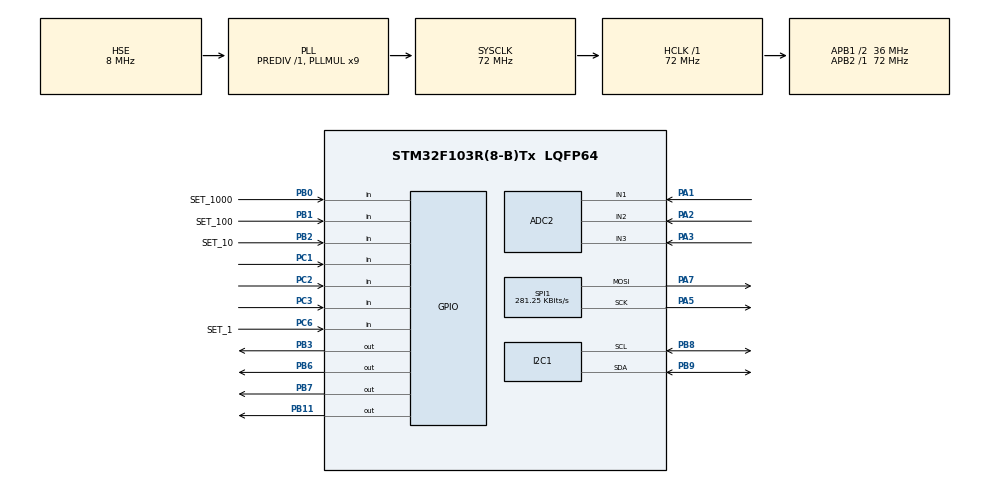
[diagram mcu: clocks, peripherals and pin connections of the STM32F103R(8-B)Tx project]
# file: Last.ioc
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ADC2.Channel-0\#ChannelRegularConversion=ADC_CHANNEL_1
ADC2.Channel-1\#ChannelRegularConversion=ADC_CHANNEL_2
ADC2.Channel-2\#ChannelRegularConversion=ADC_CHANNEL_3
ADC2.NbrOfConversion=3
ADC2.NbrOfConversionFlag=1
ADC2.Rank-0\#ChannelRegularConversion=1
ADC2.Rank-1\#ChannelRegularConversion=2
ADC2.Rank-2\#ChannelRegularConversion=3
ADC2.SamplingTime-0\#ChannelRegularConversion=ADC_SAMPLETIME_28CYCLES_5
ADC2.SamplingTime-1\#ChannelRegularConversion=ADC_SAMPLETIME_28CYCLES_5
ADC2.SamplingTime-2\#ChannelRegularConversion=ADC_SAMPLETIME_28CYCLES_5
Mcu.Family=STM32F1
Mcu.Name=STM32F103R(8-B)Tx
Mcu.Package=LQFP64
NVIC.PriorityGroup=NVIC_PRIORITYGROUP_4
NVIC.TIM3_IRQn=true\:0\:0\:false\:false\:true\:true\:true\:true
PA1.Signal=ADCx_IN1
PA13.Mode=Serial_Wire
PA13.Signal=SYS_JTMS-SWDIO
PA14.Mode=Serial_Wire
PA14.Signal=SYS_JTCK-SWCLK
PA2.Signal=ADCx_IN2
PA3.Signal=ADCx_IN3
PA5.Mode=TX_Only_Simplex_Unidirect_Master
PA5.Signal=SPI1_SCK
PA7.Mode=TX_Only_Simplex_Unidirect_Master
PA7.Signal=SPI1_MOSI
PB0.GPIO_Label=SET_1000
PB0.GPIO_PuPd=GPIO_PULLDOWN
PB0.Signal=GPIO_Input
PB1.GPIO_Label=SET_100
PB1.GPIO_PuPd=GPIO_PULLDOWN
PB1.Signal=GPIO_Input
PB11.GPIO_PuPd=GPIO_PULLDOWN
PB11.Signal=GPIO_Output
PB2.GPIO_Label=SET_10
PB2.GPIO_PuPd=GPIO_PULLDOWN
PB2.Signal=GPIO_Input
PB3.GPIO_Speed=GPIO_SPEED_FREQ_HIGH
PB3.Signal=GPIO_Output
PB6.Signal=GPIO_Output
PB7.Signal=GPIO_Output
PB8.Mode=I2C
PB8.Signal=I2C1_SCL
PB9.Mode=I2C
PB9.Signal=I2C1_SDA
PC1.GPIO_PuPd=GPIO_PULLDOWN
PC1.Signal=GPIO_Input
PC2.GPIO_PuPd=GPIO_PULLDOWN
PC2.Signal=GPIO_Input
PC3.GPIO_PuPd=GPIO_PULLDOWN
PC3.Signal=GPIO_Input
PC6.GPIO_Label=SET_1
PC6.GPIO_PuPd=GPIO_PULLDOWN
PC6.Signal=GPIO_Input
PD0-OSC_IN.Mode=HSE-External-Oscillator
PD0-OSC_IN.Signal=RCC_OSC_IN
PD1-OSC_OUT.Mode=HSE-External-Oscillator
PD1-OSC_OUT.Signal=RCC_OSC_OUT
ProjectManager.HeapSize=0x200
ProjectManager.StackSize=0x400
ProjectManager.TargetToolchain=STM32CubeIDE
RCC.ADCPresc=RCC_ADCPCLK2_DIV6
RCC.AHBFreq_Value=72000000
RCC.APB1CLKDivider=RCC_HCLK_DIV2
RCC.APB1Freq_Value=36000000
RCC.APB1TimFreq_Value=72000000
RCC.APB2Freq_Value=72000000
RCC.APB2TimFreq_Value=72000000
RCC.HCLKFreq_Value=72000000
RCC.PLLMUL=RCC_PLL_MUL9
RCC.PLLSourceVirtual=RCC_PLLSOURCE_HSE
RCC.SYSCLKFreq_VALUE=72000000
RCC.SYSCLKSource=RCC_SYSCLKSOURCE_PLLCLK
RCC.USBFreq_Value=72000000
SH.ADCx_IN1.0=ADC2_IN1,IN1
SH.ADCx_IN2.0=ADC2_IN2,IN2
SH.ADCx_IN3.0=ADC2_IN3,IN3
SPI1.BaudRatePrescaler=SPI_BAUDRATEPRESCALER_256
SPI1.CalculateBaudRate=281.25 KBits/s
SPI1.Direction=SPI_DIRECTION_2LINES
SPI1.Mode=SPI_MODE_MASTER
SPI1.VirtualType=VM_MASTER
TIM1.AutoReloadPreload=TIM_AUTORELOAD_PRELOAD_ENABLE
TIM1.Period=0xffff-1
TIM1.Prescaler=72-1
TIM2.AutoReloadPreload=TIM_AUTORELOAD_PRELOAD_ENABLE
TIM2.Period=65535-1
TIM2.Prescaler=72-1
TIM3.AutoReloadPreload=TIM_AUTORELOAD_PRELOAD_ENABLE
TIM3.Period=10
TIM3.Prescaler=7199
TIM4.AutoReloadPreload=TIM_AUTORELOAD_PRELOAD_ENABLE
TIM4.Period=255
TIM4.Prescaler=47999
VP_TIM1_VS_ClockSourceINT.Mode=Internal
VP_TIM2_VS_ClockSourceINT.Mode=Internal
VP_TIM3_VS_ClockSourceINT.Mode=Internal
VP_TIM4_VS_ClockSourceINT.Mode=Internal
board=custom

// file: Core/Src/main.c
/* USER CODE BEGIN Header */
/**
 ******************************************************************************
 * @file           : main.c
 * @brief          : Main program body
 ******************************************************************************
 * @attention
 *
 * Copyright (c) 2024 STMicroelectronics.
 * All rights reserved.
 *
 * This software is licensed under terms that can be found in the LICENSE file
 * in the root directory of this software component.
 * If no LICENSE file comes with this software, it is provided AS-IS.
 *
 ******************************************************************************
 */
/* USER CODE END Header */
#include "main.h"

/* USER CODE BEGIN Includes */
#include "ssd1306_fonts.h"
#include "ssd1306_tests.h"
#include "stdio.h"
#include "math.h"
/* USER CODE END Includes */

/* USER CODE BEGIN PD */
#define DS18B20_PORT GPIOB
#define DS18B20_PIN GPIO_PIN_14
#define ADC_BUF_SIZE 4
#define VREF 3310
#define DELAY_COND 6
#define DELAY_MOIST 1
#define BASELINE_TEMP 25.0
#define TEMP_COMP_COEFF 0.02  // 2% per degree Celsius
#define PI 3.14

/* USER CODE END PD */

ADC_HandleTypeDef hadc2;

I2C_HandleTypeDef hi2c1;

SPI_HandleTypeDef hspi1;

TIM_HandleTypeDef htim1;
TIM_HandleTypeDef htim2;
TIM_HandleTypeDef htim3;
TIM_HandleTypeDef htim4;

/* USER CODE BEGIN PV */
float EC_FACTOR;
uint32_t delay_time = 20000; // Initial delay time in microseconds
uint32_t delay_band = 1000; // Initial delay band in microseconds
uint8_t i=0;
uint8_t j=0;
uint8_t data_rdy=0;
uint32_t counter=0;
uint32_t counter2=0;
uint16_t counterFREQ=0;
int32_t PWM_loop=0;
uint16_t timeout=0;
float moist_offset=0;
float av_moist_sum=0;
float final_average_cond=0;
float av_cond=0;
float conductivity=0;
float resistance=0;
float av_moist=0;
float percentage_moist=0;
float percentage_moist2=0;
float Temp=0;
float Temp2=0;
float Temperature=0;
uint8_t Presence=0;
uint8_t Temp_byte1,Temp_byte2;
uint16_t TEMP =0;;
uint16_t TempInt;

const float CALIBRATION_FACTORX1=0.86;
const float CALIBRATION_FACTORX10=0.50;
const float CALIBRATION_FACTORX100=0.09;
const float CALIBRATION_FACTORX1000=0.01;

char bufferResistance[200];
char bufferConduct[200];
char bufferConduct2[200];
char bufferMoist[200];
char bufferTemp[200];
char bufferDs18b20[200];
char bufferTempInside[200];
char bufferVref[200];
char bufferDS18B20[200];
char bufferSET1[200];
char bufferSET10[200];
char bufferSET100[200];
char bufferSET1000[200];
char bufferFREQ[200];
char adcbuffer1[20];
char adcbuffer2[20];
uint8_t SET1=0;
uint8_t SET10=0;
uint8_t SET100=0;
uint8_t SET1000=0;
uint16_t conductraw=0;
uint16_t tempraw=0;
uint16_t moistureraw=0;
uint32_t value[3]; // adc valuyes
float temp1;//
float MIN_VOLTAGE = 600;
float MAX_VOLTAGE = 2130;
uint32_t adc_buffer[ADC_BUF_SIZE];
float voltage_buffer[ADC_BUF_SIZE];
uint8_t adc_ready=0;
uint8_t pwmflagfinished=0;
volatile uint8_t counterflagPWM=0;
volatile uint8_t counterflagPWM2=0;

uint32_t cond;
uint32_t vref_int_mv;
uint32_t moist;
uint32_t inTempC;
/* USER CODE END PV */

void SystemClock_Config(void);
static void MX_GPIO_Init(void);
static void MX_I2C1_Init(void);
static void MX_ADC2_Init(void);
static void MX_TIM1_Init(void);
static void MX_TIM4_Init(void);
static void MX_TIM3_Init(void);
static void MX_TIM2_Init(void);
static void MX_SPI1_Init(void);
/* USER CODE BEGIN PFP */
float new_calculateECSET1(float voltage,float Temp){
	const float voltagePerOhm = 20;  // Voltage increase per ohm
	float resistance = voltage / voltagePerOhm;
	float resistivity = resistance * (6.0*3.14);
	float uncompensatedConductivity  = 0;
	if (resistivity != 0) {
		uncompensatedConductivity  = (1 / resistivity) * 1000;  // Convert S/m to mS/cm
	}
	float tempCompensationFactor = 1 + (TEMP_COMP_COEFF * (Temp - BASELINE_TEMP));
	float compensatedConductivity = uncompensatedConductivity * tempCompensationFactor;
	return compensatedConductivity;
}
float new_calculateRSET1(float voltage){
	const float voltagePerOhm = 20;  // Voltage increase per ohm
	float resistance = voltage / voltagePerOhm;
	return resistance;
}
float new_calculateECSET10(float voltage,float Temp){
	const float voltagePerOhm = 3.1;  // Voltage increase per ohm
	float resistance = voltage / voltagePerOhm;
	float resistivity = resistance * (6.0*3.14);
	float uncompensatedConductivity  = 0;
	if (resistivity != 0) {
		uncompensatedConductivity  = (1 / resistivity) * 1000;  // Convert S/m to mS/cm
	}
	float tempCompensationFactor = 1 + (TEMP_COMP_COEFF * (Temp - BASELINE_TEMP));
	float compensatedConductivity = uncompensatedConductivity * tempCompensationFactor;
	return compensatedConductivity;
}
float new_calculateRSET10(float voltage){
	const float voltagePerOhm = 3.1;  // Voltage increase per ohm
	float resistance = voltage / voltagePerOhm;
	return resistance;
}
float new_calculateECSET100(float voltage,float Temp){
	const float voltagePerOhm = 0.31;  // Voltage increase per ohm
	float resistance = voltage / voltagePerOhm;
	float resistivity = resistance * (6.0*3.14);
	float uncompensatedConductivity  = 0;
	if (resistivity != 0) {
		uncompensatedConductivity  = (1 / resistivity) * 1000000;  // Convert S/m to uS/cm
	}
	float tempCompensationFactor = 1 + (TEMP_COMP_COEFF * (Temp - BASELINE_TEMP));
	float compensatedConductivity = uncompensatedConductivity * tempCompensationFactor;
	return compensatedConductivity;
}
float new_calculateRSET100(float voltage){
	const float voltagePerOhm = 0.31;  // Voltage increase per ohm
	float resistance = voltage / voltagePerOhm;
	return resistance;
}
float new_calculateECSET1000(float voltage,float Temp){
	const float voltagePerOhm = 0.031;  // Voltage increase per ohm
	float resistance = voltage / voltagePerOhm;
	float resistivity = resistance * (6.0*3.14);
	float uncompensatedConductivity  = 0;
	if (resistivity != 0) {
		uncompensatedConductivity  = (1 / resistivity) * 1000000;  // Convert S/m to uS/cm
	}
	float tempCompensationFactor = 1 + (TEMP_COMP_COEFF * (Temp - BASELINE_TEMP));
	float compensatedConductivity = uncompensatedConductivity * tempCompensationFactor;
	return compensatedConductivity;
}
float new_calculateRSET1000(float voltage){
	const float voltagePerOhm = 0.031;  // Voltage increase per ohm
	float resistance = voltage / voltagePerOhm;
	return resistance;
}

float calculateECSET1(float voltage,float Temp) {
	if((voltage>2900)&&(voltage<=3000))
	{
		const float voltagePerOhm = 0.1;  // Voltage increase per ohm
		float resistance = voltage / voltagePerOhm;
		float uncompensatedConductivity  = 0;
		if (resistance != 0) {
			uncompensatedConductivity  = (1 / resistance) * 10;  // Convert S/m to mS/cm
		}
		float tempCompensationFactor = 1 + (TEMP_COMP_COEFF * (Temp - BASELINE_TEMP));
		float compensatedConductivity = uncompensatedConductivity * tempCompensationFactor;
		return compensatedConductivity;
	}
	if((voltage>2600)&&(voltage<=2900))
	{
		const float voltagePerOhm = 0.5;  // Voltage increase per ohm
		float resistance = voltage / voltagePerOhm;
		float uncompensatedConductivity  = 0;
		if (resistance != 0) {
			uncompensatedConductivity  = (1 / resistance) * 10;  // Convert S/m to mS/cm
		}
		float tempCompensationFactor = 1 + (TEMP_COMP_COEFF * (Temp - BASELINE_TEMP));
		float compensatedConductivity = uncompensatedConductivity * tempCompensationFactor;
		return compensatedConductivity;
	}
	if((voltage>2300)&&(voltage<=2600))
	{
		const float voltagePerOhm = 5;  // Voltage increase per ohm
		float resistance = voltage / voltagePerOhm;
		float uncompensatedConductivity  = 0;
		if (resistance != 0) {
			uncompensatedConductivity  = (1 / resistance) * 10;  // Convert S/m to mS/cm
		}
		float tempCompensationFactor = 1 + (TEMP_COMP_COEFF * (Temp - BASELINE_TEMP));
		float compensatedConductivity = uncompensatedConductivity * tempCompensationFactor;
		return compensatedConductivity;
	}
	if((voltage>2000)&&(voltage<=2300))
	{
		const float voltagePerOhm = 20;  // Voltage increase per ohm
		float resistance = voltage / voltagePerOhm;
		float uncompensatedConductivity  = 0;
		if (resistance != 0) {
			uncompensatedConductivity  = (1 / resistance) * 10;  // Convert S/m to mS/cm
		}
		float tempCompensationFactor = 1 + (TEMP_COMP_COEFF * (Temp - BASELINE_TEMP));
		float compensatedConductivity = uncompensatedConductivity * tempCompensationFactor;
		return compensatedConductivity;
	}
	if((voltage>1700)&&(voltage<=2000))
	{
		const float voltagePerOhm = 40;  // Voltage increase per ohm
		float resistance = voltage / voltagePerOhm;
		float uncompensatedConductivity  = 0;
		if (resistance != 0) {
			uncompensatedConductivity  = (1 / resistance) * 10;  // Convert S/m to mS/cm
		}
		float tempCompensationFactor = 1 + (TEMP_COMP_COEFF * (Temp - BASELINE_TEMP));
		float compensatedConductivity = uncompensatedConductivity * tempCompensationFactor;
		return compensatedConductivity;
	}
	if((voltage>1500)&&(voltage<=1700))
	{
		const float voltagePerOhm = 75;  // Voltage increase per ohm
		float resistance = voltage / voltagePerOhm;
		float uncompensatedConductivity  = 0;
		if (resistance != 0) {
			uncompensatedConductivity  = (1 / resistance) * 10;  // Convert S/m to mS/cm
		}
		float tempCompensationFactor = 1 + (TEMP_COMP_COEFF * (Temp - BASELINE_TEMP));
		float compensatedConductivity = uncompensatedConductivity * tempCompensationFactor;
		return compensatedConductivity;
	}
	if((voltage>1200)&&(voltage<=1500))
	{
		const float voltagePerOhm = 150;  // Voltage increase per ohm
		float resistance = voltage / voltagePerOhm;
		float uncompensatedConductivity  = 0;
		if (resistance != 0) {
			uncompensatedConductivity  = (1 / resistance) * 10;  // Convert S/m to mS/cm
		}
		float tempCompensationFactor = 1 + (TEMP_COMP_COEFF * (Temp - BASELINE_TEMP));
		float compensatedConductivity = uncompensatedConductivity * tempCompensationFactor;
		return compensatedConductivity;
	}
	if((voltage>1000)&&(voltage<=1200))
	{
		const float voltagePerOhm = 200;  // Voltage increase per ohm
		float resistance = voltage / voltagePerOhm;
		float uncompensatedConductivity  = 0;
		if (resistance != 0) {
			uncompensatedConductivity  = (1 / resistance) * 10;  // Convert S/m to mS/cm
		}
		float tempCompensationFactor = 1 + (TEMP_COMP_COEFF * (Temp - BASELINE_TEMP));
		float compensatedConductivity = uncompensatedConductivity * tempCompensationFactor;
		return compensatedConductivity;

	}
	if((voltage>800)&&(voltage<=1000))
	{
		const float voltagePerOhm = 300;  // Voltage increase per ohm
		float resistance = voltage / voltagePerOhm;
		float uncompensatedConductivity  = 0;
		if (resistance != 0) {
			uncompensatedConductivity  = (1 / resistance) * 10;  // Convert S/m to mS/cm
		}
		float tempCompensationFactor = 1 + (TEMP_COMP_COEFF * (Temp - BASELINE_TEMP));
		float compensatedConductivity = uncompensatedConductivity * tempCompensationFactor;
		return compensatedConductivity;

	}
	if((voltage>700)&&(voltage<=800))
	{
		const float voltagePerOhm = 400;  // Voltage increase per ohm
		float resistance = voltage / voltagePerOhm;
		float uncompensatedConductivity  = 0;
		if (resistance != 0) {
			uncompensatedConductivity  = (1 / resistance) * 10;  // Convert S/m to mS/cm
		}
		float tempCompensationFactor = 1 + (TEMP_COMP_COEFF * (Temp - BASELINE_TEMP));
		float compensatedConductivity = uncompensatedConductivity * tempCompensationFactor;
		return compensatedConductivity;

	}
	if((voltage>600)&&(voltage<=700))
	{
		const float voltagePerOhm = 450;  // Voltage increase per ohm
		float resistance = voltage / voltagePerOhm;
		float uncompensatedConductivity  = 0;
		if (resistance != 0) {
			uncompensatedConductivity  = (1 / resistance) * 10;  // Convert S/m to mS/cm
		}
		float tempCompensationFactor = 1 + (TEMP_COMP_COEFF * (Temp - BASELINE_TEMP));
		float compensatedConductivity = uncompensatedConductivity * tempCompensationFactor;
		return compensatedConductivity;

	}
	if((voltage>0)&&(voltage<=600))
	{
		const float voltagePerOhm = 650;  // Voltage increase per ohm
		float resistance = voltage / voltagePerOhm;
		float uncompensatedConductivity  = 0;
		if (resistance != 0) {
			uncompensatedConductivity  = (1 / resistance) * 10;  // Convert S/m to mS/cm
		}
		float tempCompensationFactor = 1 + (TEMP_COMP_COEFF * (Temp - BASELINE_TEMP));
		float compensatedConductivity = uncompensatedConductivity * tempCompensationFactor;
		return compensatedConductivity;

	}

}
float calculateECSET10(float voltage,float Temp) {
	if((voltage>2900)&&(voltage<=3000))
	{
		const float voltagePerOhm = 0.0500;  // Voltage increase per ohm
		float resistance = voltage / voltagePerOhm;
		float uncompensatedConductivity  = 0;
		if (resistance != 0) {
			uncompensatedConductivity  = (1 / resistance) * 10;  // Convert S/m to mS/cm
		}
		float tempCompensationFactor = 1 + (TEMP_COMP_COEFF * (Temp - BASELINE_TEMP));
		float compensatedConductivity = uncompensatedConductivity * tempCompensationFactor;
		return compensatedConductivity;
	}
	if((voltage>2600)&&(voltage<=2900))
	{
		const float voltagePerOhm = 0.0500;  // Voltage increase per ohm
		float resistance = voltage / voltagePerOhm;
		float uncompensatedConductivity  = 0;
		if (resistance != 0) {
			uncompensatedConductivity  = (1 / resistance) * 10;  // Convert S/m to mS/cm
		}
		float tempCompensationFactor = 1 + (TEMP_COMP_COEFF * (Temp - BASELINE_TEMP));
		float compensatedConductivity = uncompensatedConductivity * tempCompensationFactor;
		return compensatedConductivity;
	}
	if((voltage>2300)&&(voltage<=2600))
	{
		const float voltagePerOhm = 0.0550;  // Voltage increase per ohm
		float resistance = voltage / voltagePerOhm;
		float uncompensatedConductivity  = 0;
		if (resistance != 0) {
			uncompensatedConductivity  = (1 / resistance) * 10;  // Convert S/m to mS/cm
		}
		float tempCompensationFactor = 1 + (TEMP_COMP_COEFF * (Temp - BASELINE_TEMP));
		float compensatedConductivity = uncompensatedConductivity * tempCompensationFactor;
		return compensatedConductivity;
	}
	if((voltage>2000)&&(voltage<=2300))
	{
		const float voltagePerOhm = 0.0570;  // Voltage increase per ohm
		float resistance = voltage / voltagePerOhm;
		float uncompensatedConductivity  = 0;
		if (resistance != 0) {
			uncompensatedConductivity  = (1 / resistance) * 10;  // Convert S/m to mS/cm
		}
		float tempCompensationFactor = 1 + (TEMP_COMP_COEFF * (Temp - BASELINE_TEMP));
		float compensatedConductivity = uncompensatedConductivity * tempCompensationFactor;
		return compensatedConductivity;
	}
	if((voltage>1700)&&(voltage<=2000))
	{
		const float voltagePerOhm = 0.0600;  // Voltage increase per ohm
		float resistance = voltage / voltagePerOhm;
		float uncompensatedConductivity  = 0;
		if (resistance != 0) {
			uncompensatedConductivity  = (1 / resistance) * 10;  // Convert S/m to mS/cm
		}
		float tempCompensationFactor = 1 + (TEMP_COMP_COEFF * (Temp - BASELINE_TEMP));
		float compensatedConductivity = uncompensatedConductivity * tempCompensationFactor;
		return compensatedConductivity;
	}
	if((voltage>1500)&&(voltage<=1700))
	{
		const float voltagePerOhm = 0.0650;  // Voltage increase per ohm
		float resistance = voltage / voltagePerOhm;
		float uncompensatedConductivity  = 0;
		if (resistance != 0) {
			uncompensatedConductivity  = (1 / resistance) * 10;  // Convert S/m to mS/cm
		}
		float tempCompensationFactor = 1 + (TEMP_COMP_COEFF * (Temp - BASELINE_TEMP));
		float compensatedConductivity = uncompensatedConductivity * tempCompensationFactor;
		return compensatedConductivity;
	}
	if((voltage>1200)&&(voltage<=1500))
	{
		const float voltagePerOhm = 0.0710;  // Voltage increase per ohm
		float resistance = voltage / voltagePerOhm;
		float uncompensatedConductivity  = 0;
		if (resistance != 0) {
			uncompensatedConductivity  = (1 / resistance) * 10;  // Convert S/m to mS/cm
		}
		float tempCompensationFactor = 1 + (TEMP_COMP_COEFF * (Temp - BASELINE_TEMP));
		float compensatedConductivity = uncompensatedConductivity * tempCompensationFactor;
		return compensatedConductivity;
	}
	if((voltage>1000)&&(voltage<=1200))
	{
		const float voltagePerOhm = 0.0750;  // Voltage increase per ohm
		float resistance = voltage / voltagePerOhm;
		float uncompensatedConductivity  = 0;
		if (resistance != 0) {
			uncompensatedConductivity  = (1 / resistance) * 10;  // Convert S/m to mS/cm
		}
		float tempCompensationFactor = 1 + (TEMP_COMP_COEFF * (Temp - BASELINE_TEMP));
		float compensatedConductivity = uncompensatedConductivity * tempCompensationFactor;
		return compensatedConductivity;

	}
	if((voltage>800)&&(voltage<=1000))
	{
		const float voltagePerOhm = 0.0800;  // Voltage increase per ohm
		float resistance = voltage / voltagePerOhm;
		float uncompensatedConductivity  = 0;
		if (resistance != 0) {
			uncompensatedConductivity  = (1 / resistance) * 10;  // Convert S/m to mS/cm
		}
		float tempCompensationFactor = 1 + (TEMP_COMP_COEFF * (Temp - BASELINE_TEMP));
		float compensatedConductivity = uncompensatedConductivity * tempCompensationFactor;
		return compensatedConductivity;

	}
	if((voltage>700)&&(voltage<=800))
	{
		const float voltagePerOhm = 0.1;  // Voltage increase per ohm
		float resistance = voltage / voltagePerOhm;
		float uncompensatedConductivity  = 0;
		if (resistance != 0) {
			uncompensatedConductivity  = (1 / resistance) * 10;  // Convert S/m to mS/cm
		}
		float tempCompensationFactor = 1 + (TEMP_COMP_COEFF * (Temp - BASELINE_TEMP));
		float compensatedConductivity = uncompensatedConductivity * tempCompensationFactor;
		return compensatedConductivity;

	}
	if((voltage>600)&&(voltage<=700))
	{
		const float voltagePerOhm = 0.2;  // Voltage increase per ohm
		float resistance = voltage / voltagePerOhm;
		float uncompensatedConductivity  = 0;
		if (resistance != 0) {
			uncompensatedConductivity  = (1 / resistance) * 10;  // Convert S/m to mS/cm
		}
		float tempCompensationFactor = 1 + (TEMP_COMP_COEFF * (Temp - BASELINE_TEMP));
		float compensatedConductivity = uncompensatedConductivity * tempCompensationFactor;
		return compensatedConductivity;

	}
	if((voltage>0)&&(voltage<=600))
	{
		const float voltagePerOhm = 0.5;  // Voltage increase per ohm
		float resistance = voltage / voltagePerOhm;
		float uncompensatedConductivity  = 0;
		if (resistance != 0) {
			uncompensatedConductivity  = (1 / resistance) * 10;  // Convert S/m to mS/cm
		}
		float tempCompensationFactor = 1 + (TEMP_COMP_COEFF * (Temp - BASELINE_TEMP));
		float compensatedConductivity = uncompensatedConductivity * tempCompensationFactor;
		return compensatedConductivity;

	}
}
	float calculateECSET100(float voltage,float Temp) {
		const float voltagePerOhm = 0.0400;  // Voltage increase per ohm
		float resistance = voltage / voltagePerOhm;
		float uncompensatedConductivity  = 0;

		if (resistance != 0) {
			uncompensatedConductivity  = (1 / resistance) * 10000;  // uS/cm
		}
		float tempCompensationFactor = 1 + (TEMP_COMP_COEFF * (Temp - BASELINE_TEMP));
		float compensatedConductivity = uncompensatedConductivity * tempCompensationFactor;
		return compensatedConductivity;

	}
	float calculateECSET1000(float voltage,float Temp) {
		const float voltagePerOhm = 0.0172;  // Voltage increase per ohm
		float resistance = voltage / voltagePerOhm;
		float uncompensatedConductivity  = 0;

		if (resistance != 0) {
			uncompensatedConductivity  = (1 / resistance) * 10000;  // uS/cm
		}
		float tempCompensationFactor = 1 + (TEMP_COMP_COEFF * (Temp - BASELINE_TEMP));
		float compensatedConductivity = uncompensatedConductivity * tempCompensationFactor;
		return compensatedConductivity;

	}

	void HAL_TIM_PeriodElapsedCallback(TIM_HandleTypeDef *htim) {
		if (htim->Instance == TIM3) {
			counter++;
			counter2++;
			if (counter>65535)
			{
				counter=0;
			}
			if (counter>30)
			{
				counterflagPWM=1;

			}
			if (counter>1000)
			{
				counterflagPWM2=1;
			}
			if(counter2>20000)
			{
				timeout=1;
			}

		}
	}

	void salinity_fertilizer() {
		if((SET1==1)||(SET10==1))
		{
			if(conductivity==0){
				for(int i=0;i<5;i++){
					ssd1306_Fill(0);
					ssd1306_UpdateScreen();
					ssd1306_SetCursor(0, 0);
					ssd1306_WriteString("NO CONDUCTIVITY ",Font_7x10,1);
					ssd1306_SetCursor(0,10);
					ssd1306_WriteString("MEASUREMENT",Font_7x10,1);
					ssd1306_SetCursor(0,20);
					ssd1306_WriteString("CAN'T ESTIMATE",Font_7x10,1);
					ssd1306_SetCursor(0,30);
					ssd1306_WriteString("SALINITY",Font_7x10,1);
					ssd1306_UpdateScreen();
					HAL_Delay(1000);
				}
			}
			if((conductivity<=2)&&(conductivity!=0))
			{
				for(int i=0;i<5;i++){
					ssd1306_Fill(0);
					ssd1306_UpdateScreen();
					ssd1306_SetCursor(0, 0);
					ssd1306_WriteString("SALINITY",Font_7x10,1);
					ssd1306_SetCursor(0,10);
					ssd1306_WriteString("LOW",Font_7x10,1);
					ssd1306_SetCursor(0,20);
					ssd1306_WriteString("GOOD FOR",Font_7x10,1);
					ssd1306_SetCursor(0,30);
					ssd1306_WriteString("CROPS",Font_7x10,1);
					ssd1306_UpdateScreen();
					HAL_Delay(1000);
				}
			}
			if((conductivity>=2)&&(conductivity<=4))
			{
				for(int i=0;i<5;i++){
					ssd1306_Fill(0);
					ssd1306_UpdateScreen();
					ssd1306_SetCursor(0, 0);
					ssd1306_WriteString("SALINITY",Font_7x10,1);
					ssd1306_SetCursor(0,10);
					ssd1306_WriteString("MODERATE",Font_7x10,1);
					ssd1306_SetCursor(0,20);
					ssd1306_WriteString("MAY HARM",Font_7x10,1);
					ssd1306_SetCursor(0,30);
					ssd1306_WriteString("CROPS",Font_7x10,1);
					ssd1306_UpdateScreen();
					HAL_Delay(1000);
				}
			}
			if((conductivity>=4)&&(conductivity!=0))
			{
				for(int i=0;i<5;i++){
					ssd1306_Fill(0);
					ssd1306_UpdateScreen();
					ssd1306_SetCursor(0, 0);
					ssd1306_WriteString("SALINITY",Font_7x10,1);
					ssd1306_SetCursor(0,10);
					ssd1306_WriteString("HIGH",Font_7x10,1);
					ssd1306_SetCursor(0,20);
					ssd1306_WriteString("BAD FOR",Font_7x10,1);
					ssd1306_SetCursor(0,30);
					ssd1306_WriteString("CROPS",Font_7x10,1);
					ssd1306_UpdateScreen();
					HAL_Delay(1000);
				}
			}
		}
		if((SET100==1)||(SET1000==1))
		{
			if(conductivity==0){
				for(int i=0;i<5;i++){
					ssd1306_Fill(0);
					ssd1306_UpdateScreen();
					ssd1306_SetCursor(0, 0);
					ssd1306_WriteString("NO CONDUCTIVITY ",Font_7x10,1);
					ssd1306_SetCursor(0,10);
					ssd1306_WriteString("MEASUREMENT",Font_7x10,1);
					ssd1306_SetCursor(0,20);
					ssd1306_WriteString("CAN'T ESTIMATE",Font_7x10,1);
					ssd1306_SetCursor(0,30);
					ssd1306_WriteString("SALINITY",Font_7x10,1);
					ssd1306_UpdateScreen();
					HAL_Delay(1000);
				}
			}
			if((conductivity<=5.55)&&(conductivity>=1.55))
			{
				for(int i=0;i<5;i++){
					ssd1306_Fill(0);
					ssd1306_UpdateScreen();
					ssd1306_SetCursor(0, 0);
					ssd1306_WriteString("SOIL",Font_7x10,1);
					ssd1306_SetCursor(0,10);
					ssd1306_WriteString("LACKS OF",Font_7x10,1);
					ssd1306_SetCursor(0,20);
					ssd1306_WriteString("NUTRITIENTS",Font_7x10,1);
					ssd1306_UpdateScreen();
					HAL_Delay(1000);
				}

			}
			if((conductivity<=2.55)&&(conductivity>=0))
			{
				for(int i=0;i<5;i++){
					ssd1306_Fill(0);
					ssd1306_UpdateScreen();
					ssd1306_SetCursor(0, 0);
					ssd1306_WriteString("SOIL",Font_7x10,1);
					ssd1306_SetCursor(0,10);
					ssd1306_WriteString("NEEDS",Font_7x10,1);
					ssd1306_SetCursor(0,20);
					ssd1306_WriteString("FERTILIZERS",Font_7x10,1);
					ssd1306_UpdateScreen();
					HAL_Delay(1000);
				}
			}
		}
		ssd1306_Fill(0);
		ssd1306_UpdateScreen();
	}

	void PWM_COND() {

		counterflagPWM=0;
		counter=0;
		do{
			delay2(delay_time);
			GPIOB->BSRR = GPIO_PIN_6; // Set Pin 7 (output high)
			delay2(delay_time); // Adjust delay time as needed
			GPIOB->BSRR = GPIO_PIN_6 << 16; // Reset Pin 7 (output low)

			delay2(delay_band);

			// Toggle GPIOB Pin 6
			//        delay2(delay_time);
			GPIOB->BSRR = GPIO_PIN_7; // Set Pin 6 (output high)
			delay2(delay_time); // Adjust delay time as needed
			GPIOB->BSRR = GPIO_PIN_7 << 16; // Reset Pin 6 (output low)
			delay2(delay_time);
		}while(counterflagPWM==0);

	}

	void PWM_MOIST(){

		counterflagPWM2=0;
		counter=0;
		// Set PB3 as output
		GPIOB->CRL &= ~(GPIO_CRL_CNF3 | GPIO_CRL_MODE3); // Clear bits
		GPIOB->CRL |= GPIO_CRL_MODE3_0; // Set pin mode to general purpose output push-pull 10MHz
		do{

			GPIOB->ODR ^= GPIO_ODR_ODR3;
			delay2(1);

		}while(counterflagPWM2==0);

		HAL_GPIO_WritePin(GPIOB, GPIO_PIN_3, 0);

	}

	void SSD1306_INITS()
	{
		ssd1306_Init();
		ssd1306_UpdateScreen();
		HAL_Delay(50);
		ssd1306_Fill(0);
		ssd1306_UpdateScreen();
		ssd1306_WriteString("Telectronio",Font_11x18,1);
		ssd1306_UpdateScreen();
		HAL_Delay(1000);
		ssd1306_Fill(0);
		ssd1306_UpdateScreen();
		HAL_Delay(50);
		ssd1306_SetCursor(0, 0);
		ssd1306_WriteString("Soil", Font_11x18,1);
		ssd1306_SetCursor(0, 19);
		ssd1306_WriteString("Meaurement", Font_11x18,1);
		ssd1306_SetCursor(0, 38);
		ssd1306_WriteString("Version1", Font_11x18,1);
		ssd1306_UpdateScreen();
		HAL_Delay(1000);
		ssd1306_Fill(0);
		ssd1306_UpdateScreen();
	}

	void delay(uint16_t delay){
		__HAL_TIM_SET_COUNTER(&htim1,0);
		while(__HAL_TIM_GET_COUNTER(&htim1)<delay);
	}

	void Set_Pin_Output(GPIO_TypeDef *GPIOx,uint16_t GPIO_Pin)
	{
		GPIO_InitTypeDef GPIO_InitStruct={0};
		GPIO_InitStruct.Pin=GPIO_Pin;
		GPIO_InitStruct.Mode=GPIO_MODE_OUTPUT_PP;
		GPIO_InitStruct.Speed=GPIO_SPEED_FREQ_LOW;
		HAL_GPIO_Init(GPIOx,&GPIO_InitStruct);
	}

	void Set_Pin_Input(GPIO_TypeDef *GPIOx,uint16_t GPIO_Pin)
	{
		GPIO_InitTypeDef GPIO_InitStruct={0};
		GPIO_InitStruct.Pin=GPIO_Pin;
		GPIO_InitStruct.Mode=GPIO_MODE_INPUT;
		GPIO_InitStruct.Pull=GPIO_NOPULL;
		HAL_GPIO_Init(GPIOx,&GPIO_InitStruct);
	}
	void Set_Pin_InputPU(GPIO_TypeDef *GPIOx,uint16_t GPIO_Pin)
	{
		GPIO_InitTypeDef GPIO_InitStruct={0};
		GPIO_InitStruct.Pin=GPIO_Pin;
		GPIO_InitStruct.Mode=GPIO_MODE_INPUT;
		GPIO_InitStruct.Pull=GPIO_PULLUP;
		HAL_GPIO_Init(GPIOx,&GPIO_InitStruct);
	}
	void Set_Pin_InputPD(GPIO_TypeDef *GPIOx,uint16_t GPIO_Pin)
	{
		GPIO_InitTypeDef GPIO_InitStruct={0};
		GPIO_InitStruct.Pin=GPIO_Pin;
		GPIO_InitStruct.Mode=GPIO_MODE_INPUT;
		GPIO_InitStruct.Pull=GPIO_PULLDOWN;
		HAL_GPIO_Init(GPIOx,&GPIO_InitStruct);
	}

	void Set_Conductivity_outputs_PD()
	{
		GPIO_InitTypeDef GPIO_InitStruct={0};
		/*Configure GPIO pins : PB6 PB7 */
		GPIO_InitStruct.Pin = GPIO_PIN_6|GPIO_PIN_7;
		GPIO_InitStruct.Mode = GPIO_MODE_OUTPUT_PP;
		GPIO_InitStruct.Pull = GPIO_PULLDOWN;
		GPIO_InitStruct.Speed = GPIO_SPEED_FREQ_HIGH;
		HAL_GPIO_Init(GPIOB, &GPIO_InitStruct);
	}
	uint8_t DS18B20_Start (void)
	{
		uint8_t Response=0;
		Set_Pin_Output(DS18B20_PORT,DS18B20_PIN);
		HAL_GPIO_WritePin(DS18B20_PORT,DS18B20_PIN,0);
		delay(480);
		Set_Pin_Input(DS18B20_PORT,DS18B20_PIN);
		delay(60);

		if(!(HAL_GPIO_ReadPin (DS18B20_PORT,DS18B20_PIN))) Response =1;
		else Response = -1;
		delay(480);
		return Response;
	}

	void DS18B20_Write (uint8_t data)
	{
		Set_Pin_Output(DS18B20_PORT,DS18B20_PIN);

		for(int i=0; i<8; i++)
		{
			if((data&(1<<i))!=0)
			{
				//write 1
				Set_Pin_Output(DS18B20_PORT,DS18B20_PIN);
				HAL_GPIO_WritePin(DS18B20_PORT,DS18B20_PIN,0);
				delay(1);
				Set_Pin_Input(DS18B20_PORT,DS18B20_PIN);
				delay(60);
			}
			else
			{
				//write 0

				Set_Pin_Output(DS18B20_PORT,DS18B20_PIN);
				HAL_GPIO_WritePin(DS18B20_PORT,DS18B20_PIN,0);
				delay(60);
				Set_Pin_Input(DS18B20_PORT,DS18B20_PIN);

			}
		}
	}

	uint8_t DS18B20_Read (void)
	{
		uint8_t value=0;
		Set_Pin_Input(DS18B20_PORT,DS18B20_PIN);

		for(int i=0;i<8;i++)
		{
			Set_Pin_Output(DS18B20_PORT,DS18B20_PIN);
			HAL_GPIO_WritePin(DS18B20_PORT,DS18B20_PIN,0);
			delay(1);
			Set_Pin_Input(DS18B20_PORT,DS18B20_PIN);
			if(HAL_GPIO_ReadPin(DS18B20_PORT,DS18B20_PIN))
			{
				value |= 1<<i; //read=1
			}
			delay(60);
		}
		return value;
	}

	float DS18B20_GetTemp(void)
	{
		Presence = DS18B20_Start();

		HAL_Delay(1);

		DS18B20_Write(0xCC); // SKIP ROM
		DS18B20_Write(0x44); // Convert T

		HAL_Delay(1);

		Presence = DS18B20_Start();

		HAL_Delay(1);

		DS18B20_Write(0xCC);
		DS18B20_Write(0xBE); // Read scratch pad

		Temp_byte1 = DS18B20_Read();
		Temp_byte2 = DS18B20_Read();
		TEMP = (Temp_byte2 << 8) | Temp_byte1;
		Temperature = (float)TEMP / 16;

		HAL_Delay(10);

		return Temperature;
	}

	void ADC_CH0(void)
	{
		ADC_ChannelConfTypeDef sConfig = {0};
		sConfig.Channel = ADC_CHANNEL_0;
		sConfig.Rank = ADC_REGULAR_RANK_1;
		sConfig.SamplingTime = ADC_SAMPLETIME_41CYCLES_5;
		if (HAL_ADC_ConfigChannel(&hadc2, &sConfig) != HAL_OK)
		{
			Error_Handler();
		}
	}
	void ADC_CH1(void)
	{
		ADC_ChannelConfTypeDef sConfig = {0};
		sConfig.Channel = ADC_CHANNEL_1;
		sConfig.Rank = ADC_REGULAR_RANK_1;
		sConfig.SamplingTime = ADC_SAMPLETIME_41CYCLES_5;
		if (HAL_ADC_ConfigChannel(&hadc2, &sConfig) != HAL_OK)
		{
			Error_Handler();
		}
	}
	void ADC_CH2(void)
	{
		ADC_ChannelConfTypeDef sConfig = {0};
		sConfig.Channel = ADC_CHANNEL_2;
		sConfig.Rank = ADC_REGULAR_RANK_1;
		sConfig.SamplingTime = ADC_SAMPLETIME_41CYCLES_5;
		if (HAL_ADC_ConfigChannel(&hadc2, &sConfig) != HAL_OK)
		{
			Error_Handler();
		}
	}
	void ADC_CH3(void)
	{
		ADC_ChannelConfTypeDef sConfig = {0};
		sConfig.Channel = ADC_CHANNEL_3;
		sConfig.Rank = ADC_REGULAR_RANK_1;
		sConfig.SamplingTime = ADC_SAMPLETIME_41CYCLES_5;
		if (HAL_ADC_ConfigChannel(&hadc2, &sConfig) != HAL_OK)
		{
			Error_Handler();
		}
	}
	float adc_value_to_voltage(uint16_t adc_value) {
		return (adc_value / 4095.0) * VREF; // 4095 for 12-bit resolution
	}

	void delay2(uint32_t delay_time) {
		for (uint32_t i = 0; i < delay_time; ++i) {
			__NOP(); // Use NOP instruction for delay
		}
	}

	void EC_out_of_range_fast()
		{
			if((final_average_cond>=3080)&& (SET1==1))
			{
				for(int i=0;i<5;i++){
					ssd1306_Fill(0);
					ssd1306_UpdateScreen();
					ssd1306_SetCursor(0, 0);
					ssd1306_WriteString("EC OUT OF RANGE ",Font_7x10,1);
					ssd1306_SetCursor(0,10);
					ssd1306_WriteString("DECREASE SENSE",Font_7x10,1);
					ssd1306_UpdateScreen();
//					conductivity=0;
					HAL_Delay(100);
				}
				//out of range
				//decrease sensitivity
			}
			if((final_average_cond>=3080)&& (SET10==1))
			{
				for(int i=0;i<5;i++){
					ssd1306_Fill(0);
					ssd1306_UpdateScreen();
					ssd1306_SetCursor(0, 0);
					ssd1306_WriteString("EC OUT OF RANGE ",Font_7x10,1);
					ssd1306_SetCursor(0,10);
					ssd1306_WriteString("DECREASE SENSE",Font_7x10,1);
					ssd1306_UpdateScreen();
					//					conductivity=0;
					HAL_Delay(100);
				}
				//out of range
				//decrease sensitivity
			}
			if((final_average_cond>=3080)&& (SET100==1))
			{
				for(int i=0;i<5;i++){
					ssd1306_Fill(0);
					ssd1306_UpdateScreen();
					ssd1306_SetCursor(0, 0);
					ssd1306_WriteString("EC OUT OF RANGE ",Font_7x10,1);
					ssd1306_SetCursor(0,10);
					ssd1306_WriteString("DECREASE SENSE",Font_7x10,1);
					ssd1306_UpdateScreen();
					//					conductivity=0;
					HAL_Delay(100);
				}
				//out of range
				//decrease sensitivity
			}
			if((final_average_cond<=650) && (SET1000==1))
			{
				for(int i=0;i<5;i++){
					ssd1306_Fill(0);
					ssd1306_UpdateScreen();
					ssd1306_SetCursor(0, 0);
					ssd1306_WriteString("EC OUT OF RANGE ",Font_7x10,1);
					ssd1306_SetCursor(0,10);
					ssd1306_WriteString("INCREASE SENSE",Font_7x10,1);
					ssd1306_UpdateScreen();
					//					conductivity=0;
					HAL_Delay(100);
				}
				//out of range
				//increase sensitivity
			}
			if((final_average_cond<=650) && (SET100==1))
			{
				for(int i=0;i<5;i++){
					ssd1306_Fill(0);
					ssd1306_UpdateScreen();
					ssd1306_SetCursor(0, 0);
					ssd1306_WriteString("EC OUT OF RANGE ",Font_7x10,1);
					ssd1306_SetCursor(0,10);
					ssd1306_WriteString("INCREASE SENSE",Font_7x10,1);
					ssd1306_UpdateScreen();
//					conductivity=0;
					HAL_Delay(100);
				}
				//out of range
				//increase sensitivity
			}
			if((final_average_cond<=650) && (SET10==1))
			{
				for(int i=0;i<5;i++){
					ssd1306_Fill(0);
					ssd1306_UpdateScreen();
					ssd1306_SetCursor(0, 0);
					ssd1306_WriteString("EC OUT OF RANGE ",Font_7x10,1);
					ssd1306_SetCursor(0,10);
					ssd1306_WriteString("INCREASE SENSE",Font_7x10,1);
					ssd1306_UpdateScreen();
					//					conductivity=0;
					HAL_Delay(100);
				}
				//out of range
				//increase sensitivity
			}
		}
	void EC_out_of_range()
	{
		if((final_average_cond>=3080)&& (SET1==1))
		{
			for(int i=0;i<5;i++){
				ssd1306_Fill(0);
				ssd1306_UpdateScreen();
				ssd1306_SetCursor(0, 0);
				ssd1306_WriteString("EC OUT OF RANGE ",Font_7x10,1);
				ssd1306_SetCursor(0,10);
				ssd1306_WriteString("DECREASE SENSE",Font_7x10,1);
				ssd1306_UpdateScreen();
				//					conductivity=0;
				HAL_Delay(1000);
			}
			//out of range
			//decrease sensitivity
		}
		if((final_average_cond>=3080)&& (SET10==1))
		{
			for(int i=0;i<5;i++){
				ssd1306_Fill(0);
				ssd1306_UpdateScreen();
				ssd1306_SetCursor(0, 0);
				ssd1306_WriteString("EC OUT OF RANGE ",Font_7x10,1);
				ssd1306_SetCursor(0,10);
				ssd1306_WriteString("DECREASE SENSE",Font_7x10,1);
				ssd1306_UpdateScreen();
				//					conductivity=0;
				HAL_Delay(1000);
			}
			//out of range
			//decrease sensitivity
		}
		if((final_average_cond>=3080)&& (SET100==1))
		{
			for(int i=0;i<5;i++){
				ssd1306_Fill(0);
				ssd1306_UpdateScreen();
				ssd1306_SetCursor(0, 0);
				ssd1306_WriteString("EC OUT OF RANGE ",Font_7x10,1);
				ssd1306_SetCursor(0,10);
				ssd1306_WriteString("DECREASE SENSE",Font_7x10,1);
				ssd1306_UpdateScreen();
				//					conductivity=0;
				HAL_Delay(1000);
			}
			//out of range
			//decrease sensitivity
		}
		if((final_average_cond<=650) && (SET1000==1))
		{
			for(int i=0;i<5;i++){
				ssd1306_Fill(0);
				ssd1306_UpdateScreen();
				ssd1306_SetCursor(0, 0);
				ssd1306_WriteString("EC OUT OF RANGE ",Font_7x10,1);
				ssd1306_SetCursor(0,10);
				ssd1306_WriteString("INCREASE SENSE",Font_7x10,1);
				ssd1306_UpdateScreen();
				//					conductivity=0;
				HAL_Delay(1000);
			}
			//out of range
			//increase sensitivity
		}
		if((final_average_cond<=650) && (SET100==1))
		{
			for(int i=0;i<5;i++){
				ssd1306_Fill(0);
				ssd1306_UpdateScreen();
				ssd1306_SetCursor(0, 0);
				ssd1306_WriteString("EC OUT OF RANGE ",Font_7x10,1);
				ssd1306_SetCursor(0,10);
				ssd1306_WriteString("INCREASE SENSE",Font_7x10,1);
				ssd1306_UpdateScreen();
				//					conductivity=0;
				HAL_Delay(1000);
			}
			//out of range
			//increase sensitivity
		}
		if((final_average_cond<=650) && (SET10==1))
		{
			for(int i=0;i<5;i++){
				ssd1306_Fill(0);
				ssd1306_UpdateScreen();
				ssd1306_SetCursor(0, 0);
				ssd1306_WriteString("EC OUT OF RANGE ",Font_7x10,1);
				ssd1306_SetCursor(0,10);
				ssd1306_WriteString("INCREASE SENSE",Font_7x10,1);
				ssd1306_UpdateScreen();
				//					conductivity=0;
				HAL_Delay(1000);
			}
			//out of range
			//increase sensitivity
		}
	}

	void Set_counterFREQ(){
		if(HAL_GPIO_ReadPin(GPIOC, GPIO_PIN_2)==1)
		{
			HAL_Delay(100);
			counterFREQ++;
		}
		if(counterFREQ==0){
			delay_time = 10000; // 100HZ
			delay_band = 5000; // Initial delay band in microseconds
		}
		if(counterFREQ==1){
			delay_time = 1000; // 1KHZ
			delay_band = 500; // Initial delay band in microseconds
		}
		if(counterFREQ==2){
			delay_time = 100; // 10KHZ delay time in microseconds
			delay_band = 5; // Initial delay band in microseconds
		}
		if(counterFREQ==3){
			delay_time = 20; // 100KHZ Initial delay time in microseconds
			delay_band = 1; // Initial delay band in microseconds
		}
		if(counterFREQ==4){
			delay_time = 7; // 100KHZ Initial delay time in microseconds
			delay_band = 1; // Initial delay band in microseconds
		}
//		if(counterFREQ==4){
//			delay_time = 50; // Initial delay time in microseconds
//			delay_band = 2; // Initial delay band in microseconds
//		}
//		if(counterFREQ==5){
//			delay_time = 25; // Initial delay time in microseconds
//			delay_band = 1; // Initial delay band in microseconds
//		}
//		if(counterFREQ==6){
//			delay_time = 10; // Initial delay time in microseconds
//			delay_band = 1; // Initial delay band in microseconds
//		}
//		if(counterFREQ==7){
//			delay_time = 6; // Initial delay time in microseconds
//			delay_band = 1; // Initial delay band in microseconds
//		}
		if(counterFREQ>4){
			counterFREQ=0;
		}
	}

	void Set_SENSE(){
		if (HAL_GPIO_ReadPin(SET_1_GPIO_Port, SET_1_Pin) == 1) {
			SET1=1;
			SET10=0;
			SET100=0;
			SET1000=0;
			moist_offset=0;
			MIN_VOLTAGE = 1630;
			MAX_VOLTAGE = 2467;
			ssd1306_SetCursor(0, 41);
			sprintf(bufferSET1, "SENSE = x1     ");
			ssd1306_WriteString(bufferSET1, Font_6x8, 1);

		}

		if (HAL_GPIO_ReadPin(SET_10_GPIO_Port, SET_10_Pin) == 1) {
			SET1=0;
			SET10=1;
			SET100=0;
			SET1000=0;
			moist_offset=0;
			MIN_VOLTAGE = 1630;
			MAX_VOLTAGE = 2467;
			ssd1306_SetCursor(0, 41);
			sprintf(bufferSET10, "SENSE = x10     ");
			ssd1306_WriteString(bufferSET10, Font_6x8, 1);

		}

		if (HAL_GPIO_ReadPin(SET_100_GPIO_Port, SET_100_Pin) == 1) {
			SET1=0;
			SET10=0;
			SET100=1;
			SET1000=0;
			moist_offset=0;
			MIN_VOLTAGE = 1630;
			MAX_VOLTAGE = 2467;
			ssd1306_SetCursor(0, 41);
			sprintf(bufferSET100, "SENSE = x100     ");
			ssd1306_WriteString(bufferSET100, Font_6x8, 1);

		}

		if (HAL_GPIO_ReadPin(SET_1000_GPIO_Port, SET_1000_Pin) == 1) {
			SET1=0;
			SET10=0;
			SET100=0;
			SET1000=1;
			moist_offset=0;
			MIN_VOLTAGE = 1630;
			MAX_VOLTAGE = 2467;
			ssd1306_SetCursor(0, 41);
			sprintf(bufferSET1000, "SENSE = x1000     ");
			ssd1306_WriteString(bufferSET1000, Font_6x8, 1);

		}
	}

	void Set_counterFREQ_ssd1306(){
		if (counterFREQ==0){
			ssd1306_SetCursor(0,51);
			sprintf(bufferFREQ,"Frequency:0 100Hz   ");
			ssd1306_WriteString(bufferFREQ, Font_6x8, 1);
		}
		if (counterFREQ==1){
			ssd1306_SetCursor(0,51);
			sprintf(bufferFREQ,"Frequency:1 1KHz  ");
			ssd1306_WriteString(bufferFREQ, Font_6x8, 1);
		}
		if (counterFREQ==2){
			ssd1306_SetCursor(0,51);
			sprintf(bufferFREQ,"Frequency:2 10KHz  ");
			ssd1306_WriteString(bufferFREQ, Font_6x8, 1);
		}
		if (counterFREQ==3){
			ssd1306_SetCursor(0,51);
			sprintf(bufferFREQ,"Frequency:3 50KHz  ");
			ssd1306_WriteString(bufferFREQ, Font_6x8, 1);
		}
		if (counterFREQ==4){
			ssd1306_SetCursor(0,51);
			sprintf(bufferFREQ,"Frequency:4 100KHz  ");
			ssd1306_WriteString(bufferFREQ, Font_6x8, 1);
		}
//		if (counterFREQ==5){
//			ssd1306_SetCursor(0,51);
//			sprintf(bufferFREQ,"Frequency:5 75KHz  ");
//			ssd1306_WriteString(bufferFREQ, Font_6x8, 1);
//		}
//		if (counterFREQ==6){
//			ssd1306_SetCursor(0,51);
//			sprintf(bufferFREQ,"Frequency:6 133KHz  ");
//			ssd1306_WriteString(bufferFREQ, Font_6x8, 1);
//		}
//		if (counterFREQ==7){
//			ssd1306_SetCursor(0,51);
//			sprintf(bufferFREQ,"Frequency:7 200KHz  ");
//			ssd1306_WriteString(bufferFREQ, Font_6x8, 1);
//		}
	}

	void send_data() {
	    // Format the data
	    sprintf(bufferConduct, "R %.fmV %.f Ohm", final_average_cond, resistance);
	    sprintf(bufferMoist, "Moist %.1fV %.1f%%", av_moist_sum, percentage_moist2);
	    sprintf(bufferDs18b20, "ds18b20 %.2fC", Temp);

	    // Choose the correct buffer for conductivity based on settings
	    if (SET1 == 1 || SET10 == 1) {
	        sprintf(bufferConduct2, "EC %.3f mS/cm", conductivity);
	    } else if (SET100 == 1 || SET1000 == 1) {
	        sprintf(bufferConduct2, "EC %.3f uS/cm", conductivity);
	    }

	    // Format the SENSE settings
	    if (HAL_GPIO_ReadPin(SET_1_GPIO_Port, SET_1_Pin) == 1) {
	        sprintf(bufferSET1, "SENSE = x1");
	    } else if (HAL_GPIO_ReadPin(SET_10_GPIO_Port, SET_10_Pin) == 1) {
	        sprintf(bufferSET10, "SENSE = x10");
	    } else if (HAL_GPIO_ReadPin(SET_100_GPIO_Port, SET_100_Pin) == 1) {
	        sprintf(bufferSET100, "SENSE = x100");
	    } else if (HAL_GPIO_ReadPin(SET_1000_GPIO_Port, SET_1000_Pin) == 1) {
	        sprintf(bufferSET1000, "SENSE = x1000");
	    }

	    // Format the frequency setting
	    if (counterFREQ == 0) {
	        sprintf(bufferFREQ, "Frequency: 0 100Hz");
	    } else if (counterFREQ == 1) {
	        sprintf(bufferFREQ, "Frequency: 1 1KHz");
	    } else if (counterFREQ == 2) {
	        sprintf(bufferFREQ, "Frequency: 2 10KHz");
	    } else if (counterFREQ == 3) {
	        sprintf(bufferFREQ, "Frequency: 3 50KHz");
	    } else if (counterFREQ == 4) {
	        sprintf(bufferFREQ, "Frequency: 4 100KHz");
	    }

	    // Transmit the data over SPI
	    HAL_SPI_Transmit(&hspi1, (uint8_t*)bufferConduct, strlen(bufferConduct), HAL_MAX_DELAY);
	    HAL_SPI_Transmit(&hspi1, (uint8_t*)bufferMoist, strlen(bufferMoist), HAL_MAX_DELAY);
	    HAL_SPI_Transmit(&hspi1, (uint8_t*)bufferDs18b20, strlen(bufferDs18b20), HAL_MAX_DELAY);
	    HAL_SPI_Transmit(&hspi1, (uint8_t*)bufferConduct2, strlen(bufferConduct2), HAL_MAX_DELAY);

	    if (HAL_GPIO_ReadPin(SET_1_GPIO_Port, SET_1_Pin) == 1) {
	        HAL_SPI_Transmit(&hspi1, (uint8_t*)bufferSET1, strlen(bufferSET1), HAL_MAX_DELAY);
	    } else if (HAL_GPIO_ReadPin(SET_10_GPIO_Port, SET_10_Pin) == 1) {
	        HAL_SPI_Transmit(&hspi1, (uint8_t*)bufferSET10, strlen(bufferSET10), HAL_MAX_DELAY);
	    } else if (HAL_GPIO_ReadPin(SET_100_GPIO_Port, SET_100_Pin) == 1) {
	        HAL_SPI_Transmit(&hspi1, (uint8_t*)bufferSET100, strlen(bufferSET100), HAL_MAX_DELAY);
	    } else if (HAL_GPIO_ReadPin(SET_1000_GPIO_Port, SET_1000_Pin) == 1) {
	        HAL_SPI_Transmit(&hspi1, (uint8_t*)bufferSET1000, strlen(bufferSET1000), HAL_MAX_DELAY);
	    }

	    HAL_SPI_Transmit(&hspi1, (uint8_t*)bufferFREQ, strlen(bufferFREQ), HAL_MAX_DELAY);
	}

void conductonly(){
	if((HAL_GPIO_ReadPin(GPIOC, GPIO_PIN_1)==1)&((SET1||SET10)||SET100||SET1000))
	{
		data_rdy=0;
		counter2=0;
		HAL_GPIO_WritePin(GPIOB, GPIO_PIN_11, 0);

		if(HAL_GPIO_ReadPin(GPIOC, GPIO_PIN_1)==1){
								av_cond=0;
								conductivity=0;
								resistance=0;
								final_average_cond=0;
								Temp=0;
								Temp2=0;

								ssd1306_Fill(0);
								ssd1306_UpdateScreen();
								ssd1306_SetCursor(0, 0);
								ssd1306_WriteString("Measuring",Font_7x10,1);
								ssd1306_SetCursor(0, 10);
								ssd1306_WriteString("Resistance...",Font_7x10,1);
								ssd1306_UpdateScreen();
								ssd1306_Fill(0);
								HAL_Delay(50);

								ADC_CH1();
								for(int i=0;i<50;i++)
								{
									PWM_COND();
								}

								float av_cond_sum = 0;

								for(int j = 0; j < 10; j++) {

									HAL_ADC_Start(&hadc2);
									PWM_COND();
									float av_cond = 0; // Initialize av_cond for each iteration

									for(int i = 0; i < 10; i++) {

										PWM_COND();
										HAL_ADC_PollForConversion(&hadc2, 1);
										adc_buffer[0] = HAL_ADC_GetValue(&hadc2);
										voltage_buffer[0] = adc_value_to_voltage(adc_buffer[0]);
										av_cond += voltage_buffer[0] / 10; // Accumulate the value

									}

									HAL_ADC_Stop(&hadc2);
									HAL_Delay(10);

									//						Set_Conductivity_outputs_PD();
									//

									// Add the average of this iteration to av_cond_sum
									av_cond_sum += av_cond;
								}

								// Calculate the final average
								final_average_cond = av_cond_sum / 10;
								ssd1306_UpdateScreen();
								ssd1306_SetCursor(0, 0);
								ssd1306_WriteString("OK",Font_7x10,1);
								ssd1306_UpdateScreen();
								ssd1306_Fill(0);
								HAL_Delay(100);

								for(i=0;i<10;i++)
								{
									Temp=DS18B20_GetTemp();
									Temp2+=Temp;
									HAL_Delay(10);
								}
								Temp=Temp2/10;
								ssd1306_UpdateScreen();
								ssd1306_SetCursor(0, 0);
								ssd1306_WriteString("Temp Measure",Font_7x10,1);
								ssd1306_UpdateScreen();

								ssd1306_Fill(0);
								ssd1306_UpdateScreen();
								ssd1306_SetCursor(5,20);
								ssd1306_WriteString("Finished",Font_11x18,1);
								ssd1306_UpdateScreen();
								HAL_Delay(100);
								if(SET1==1)
								{
									conductivity=new_calculateECSET1(final_average_cond,Temp);
									resistance=new_calculateRSET1(final_average_cond);
								}
								if(SET10==1)
								{
									conductivity=new_calculateECSET10(final_average_cond,Temp);
									resistance=new_calculateRSET10(final_average_cond);
								}
								if(SET100==1)
								{
									conductivity=new_calculateECSET100(final_average_cond,Temp);
									resistance=new_calculateRSET100(final_average_cond);
								}
								if(SET1000==1)
								{
									conductivity=new_calculateECSET1000(final_average_cond,Temp);
									resistance=new_calculateRSET1000(final_average_cond);
								}
								HAL_Delay(200);
								EC_out_of_range_fast();
			//					salinity_fertilizer();
								ssd1306_Fill(0);
								ssd1306_UpdateScreen();
								data_rdy=1;

							}

		}
}
	void moistconduct(){
		if((HAL_GPIO_ReadPin(GPIOC, GPIO_PIN_3)==1)&((SET1||SET10)||SET100||SET1000))
		{
			data_rdy=0;
			counter2=0;
			HAL_GPIO_WritePin(GPIOB, GPIO_PIN_11, 0);
				if(HAL_GPIO_ReadPin(GPIOC, GPIO_PIN_3)==1)
				{

					av_cond=0;
					av_moist=0;
					final_average_cond=0;
					Temp=0;
					Temp2=0;

					ssd1306_Fill(0);
					ssd1306_UpdateScreen();
					ssd1306_SetCursor(0, 0);
					ssd1306_WriteString("Preparing ",Font_7x10,1);
					ssd1306_SetCursor(0, 10);
					ssd1306_WriteString("device for ",Font_7x10,1);
					ssd1306_SetCursor(0,20);
					ssd1306_WriteString("moisture ",Font_7x10,1);
					ssd1306_SetCursor(0,30);
					ssd1306_WriteString("measurement...",Font_7x10,1);
					ssd1306_UpdateScreen();
					for(i=0;i<15;i++)
					{
						PWM_MOIST();
					}

					ssd1306_Fill(0);
					ssd1306_UpdateScreen();
					ssd1306_SetCursor(0, 0);
					ssd1306_WriteString("Measuring",Font_7x10,1);
					ssd1306_SetCursor(0, 10);
					ssd1306_WriteString("Moisture...",Font_7x10,1);
					ssd1306_UpdateScreen();
					ssd1306_Fill(0);

					ADC_CH2();

					// Inside your loop
					percentage_moist2 = 0; // Initialize averaged percentage variable

					av_moist_sum=0;

					for (j = 0; j < 4; j++) {
						percentage_moist=0;
						av_moist = 0; // Reset av_moist for each iteration
						PWM_MOIST();
						HAL_ADC_Start(&hadc2);
						for (i = 0; i < 5; i++) {
							HAL_ADC_PollForConversion(&hadc2, 1);
							adc_buffer[1] = HAL_ADC_GetValue(&hadc2);
							voltage_buffer[1] = adc_value_to_voltage(adc_buffer[1]);
							av_moist += voltage_buffer[1] / 5;
							percentage_moist = 100.0-(((((av_moist+moist_offset) - MIN_VOLTAGE)) / (MAX_VOLTAGE - MIN_VOLTAGE)) * 100.0);
						}
						HAL_ADC_Stop(&hadc2);

						// Calculate percentage_moist for this iteration
						av_moist_sum+=(av_moist+moist_offset);

						// Accumulate the calculated percentage
						percentage_moist2 += percentage_moist;

					}

					// Calculate the average of percentage_moist over 15 measurements
					av_moist_sum/=4;
					percentage_moist2 /= 4;
					// Manipulate the last value of percentage_moist2
					if (percentage_moist2 > 100) {
						percentage_moist2 = 100;
					} else if (percentage_moist2 < 0) {
						percentage_moist2 = 0;
					}

					ssd1306_Fill(0);
					ssd1306_UpdateScreen();
					ssd1306_SetCursor(0, 0);
					ssd1306_WriteString("Measuring",Font_7x10,1);
					ssd1306_SetCursor(0, 10);
					ssd1306_WriteString("Resistance...",Font_7x10,1);
					ssd1306_UpdateScreen();
					ssd1306_Fill(0);
					HAL_Delay(1000);

					ADC_CH1();
					for(int i=0;i<50;i++)
					{
						PWM_COND();
					}

					float av_cond_sum = 0;

					for(int j = 0; j < 15; j++) {

						HAL_ADC_Start(&hadc2);
						PWM_COND();
						float av_cond = 0; // Initialize av_cond for each iteration

						for(int i = 0; i < 30; i++) {

							PWM_COND();
							HAL_ADC_PollForConversion(&hadc2, 1);
							adc_buffer[0] = HAL_ADC_GetValue(&hadc2);
							voltage_buffer[0] = adc_value_to_voltage(adc_buffer[0]);
							av_cond += voltage_buffer[0] / 30; // Accumulate the value

						}

						HAL_ADC_Stop(&hadc2);
						HAL_Delay(100);

						//						Set_Conductivity_outputs_PD();
						//

						// Add the average of this iteration to av_cond_sum
						av_cond_sum += av_cond;
					}

					// Calculate the final average
					final_average_cond = av_cond_sum / 15;
					ssd1306_UpdateScreen();
					ssd1306_SetCursor(0, 0);
					ssd1306_WriteString("Measuring",Font_7x10,1);
					ssd1306_SetCursor(0, 10);
					ssd1306_WriteString("Temperature...",Font_7x10,1);
					ssd1306_UpdateScreen();
					ssd1306_Fill(0);
					HAL_Delay(1000);

					for(i=0;i<10;i++)
					{
						Temp=DS18B20_GetTemp();
						Temp2+=Temp;
						HAL_Delay(10);
					}
					Temp=Temp2/10;

					ssd1306_Fill(0);
					ssd1306_UpdateScreen();
					ssd1306_SetCursor(5,20);
					ssd1306_WriteString("Finished",Font_11x18,1);
					ssd1306_UpdateScreen();
					HAL_Delay(1000);
					if(SET1==1)
					{
						conductivity=new_calculateECSET1(final_average_cond,Temp);
						resistance=new_calculateRSET1(final_average_cond);
					}
					if(SET10==1)
					{
						conductivity=new_calculateECSET10(final_average_cond,Temp);
						resistance=new_calculateRSET10(final_average_cond);
					}
					if(SET100==1)
					{
						conductivity=new_calculateECSET100(final_average_cond,Temp);
						resistance=new_calculateRSET100(final_average_cond);
					}
					if(SET1000==1)
					{
						conductivity=new_calculateECSET1000(final_average_cond,Temp);
						resistance=new_calculateRSET1000(final_average_cond);
					}
					HAL_Delay(200);
					EC_out_of_range();
//					salinity_fertilizer();
					ssd1306_Fill(0);
					ssd1306_UpdateScreen();
					data_rdy=1;
				}

		}

	}

/* USER CODE END PFP */

int main(void)
{

  /* MCU Configuration--------------------------------------------------------*/

  /* Reset of all peripherals, Initializes the Flash interface and the Systick. */
  HAL_Init();

  /* Configure the system clock */
  SystemClock_Config();

  /* Initialize all configured peripherals */
  MX_GPIO_Init();
  MX_I2C1_Init();
  MX_ADC2_Init();
  MX_TIM1_Init();
  MX_TIM4_Init();
  MX_TIM3_Init();
  MX_TIM2_Init();
  MX_SPI1_Init();
  /* USER CODE BEGIN 2 */
		SSD1306_INITS();
		HAL_ADC_Init(&hadc2);
		HAL_TIM_Base_Start(&htim1);
		HAL_TIM_Base_Start(&htim2);
		HAL_TIM_Base_Start(&htim4);

		//  PWM_BEGIN_MOIST();
		HAL_TIM_Base_Start_IT(&htim3);
		HAL_NVIC_SetPriority(TIM3_IRQn, 0, 0);  // Set priority and subpriority as needed
		HAL_NVIC_EnableIRQ(TIM3_IRQn);
		GPIOB->CRL &= ~(GPIO_CRL_CNF3 | GPIO_CRL_MODE3);
		GPIOB->CRL |= GPIO_CRL_MODE3;  // Output mode, max speed 50 MHz

		GPIOB->CRL &= ~(GPIO_CRL_MODE7 | GPIO_CRL_CNF7); // Pin 7
		GPIOB->CRL |= GPIO_CRL_MODE7_0; // Output mode, max speed 10 MHz
		GPIOB->CRL &= ~(GPIO_CRL_MODE6 | GPIO_CRL_CNF6); // Pin 6
		GPIOB->CRL |= GPIO_CRL_MODE6_0; // Output mode, max speed 10 MHz

  /* USER CODE END 2 */

  /* Infinite loop */
  /* USER CODE BEGIN WHILE */
		while (1)
		{

			Set_counterFREQ();
			//MEASURE SEQUENTIAL
			conductonly();
			moistconduct();

			//DS18B20
			Temp=DS18B20_GetTemp();

			//NTC BOARD TEMP
			ADC_CH3();
			HAL_ADC_Start(&hadc2);
			HAL_Delay(2);
			HAL_ADC_PollForConversion(&hadc2, 100);
			adc_buffer[2]=HAL_ADC_GetValue(&hadc2);
			voltage_buffer[2]=adc_value_to_voltage(adc_buffer[2]);
			HAL_ADC_Stop(&hadc2);
			HAL_Delay(2);

			ssd1306_SetCursor(0, 0);
			sprintf(bufferConduct,"R %.fmV %.f Ohm",final_average_cond,resistance);
			ssd1306_WriteString(bufferConduct,Font_6x8,1);
			ssd1306_SetCursor(0, 11);
			sprintf(bufferMoist,"Moist %.1fV %.1f%%",av_moist_sum,percentage_moist2);
			ssd1306_WriteString(bufferMoist,Font_6x8,1);
			ssd1306_SetCursor(0, 21);
			sprintf(bufferDs18b20,"ds18b20 %.2fC",Temp);
			ssd1306_WriteString(bufferDs18b20,Font_6x8,1);
			if(SET1 == 1 || SET10 ==1){
				ssd1306_SetCursor(0, 31);
				sprintf(bufferConduct2,"EC %.3f mS/cm",conductivity);
				ssd1306_WriteString(bufferConduct2,Font_6x8,1);
			}else if(SET100==1 || SET1000==1){
				ssd1306_SetCursor(0, 31);
				sprintf(bufferConduct2,"EC %.3f uS/cm",conductivity);
				ssd1306_WriteString(bufferConduct2,Font_6x8,1);
			}

			Set_SENSE();
			Set_counterFREQ_ssd1306();
			ssd1306_UpdateScreen();
			if(data_rdy){

				HAL_GPIO_WritePin(GPIOB, GPIO_PIN_11, 1);
				HAL_Delay(200);
				send_data();
				HAL_Delay(200);
				HAL_GPIO_WritePin(GPIOB, GPIO_PIN_11, 0);

				data_rdy=0;
			}
			else{
				HAL_GPIO_WritePin(GPIOB, GPIO_PIN_11, 0);
				data_rdy=0;
			}

    /* USER CODE END WHILE */

		}
}

void SystemClock_Config(void)
{
  RCC_OscInitTypeDef RCC_OscInitStruct = {0};
  RCC_ClkInitTypeDef RCC_ClkInitStruct = {0};
  RCC_PeriphCLKInitTypeDef PeriphClkInit = {0};

  /** Initializes the RCC Oscillators according to the specified parameters
  * in the RCC_OscInitTypeDef structure.
  */
  RCC_OscInitStruct.OscillatorType = RCC_OSCILLATORTYPE_HSE;
  RCC_OscInitStruct.HSEState = RCC_HSE_ON;
  RCC_OscInitStruct.HSEPredivValue = RCC_HSE_PREDIV_DIV1;
  RCC_OscInitStruct.HSIState = RCC_HSI_ON;
  RCC_OscInitStruct.PLL.PLLState = RCC_PLL_ON;
  RCC_OscInitStruct.PLL.PLLSource = RCC_PLLSOURCE_HSE;
  RCC_OscInitStruct.PLL.PLLMUL = RCC_PLL_MUL9;
  if (HAL_RCC_OscConfig(&RCC_OscInitStruct) != HAL_OK)
  {
    Error_Handler();
  }

  /** Initializes the CPU, AHB and APB buses clocks
  */
  RCC_ClkInitStruct.ClockType = RCC_CLOCKTYPE_HCLK|RCC_CLOCKTYPE_SYSCLK
                              |RCC_CLOCKTYPE_PCLK1|RCC_CLOCKTYPE_PCLK2;
  RCC_ClkInitStruct.SYSCLKSource = RCC_SYSCLKSOURCE_PLLCLK;
  RCC_ClkInitStruct.AHBCLKDivider = RCC_SYSCLK_DIV1;
  RCC_ClkInitStruct.APB1CLKDivider = RCC_HCLK_DIV2;
  RCC_ClkInitStruct.APB2CLKDivider = RCC_HCLK_DIV1;

  if (HAL_RCC_ClockConfig(&RCC_ClkInitStruct, FLASH_LATENCY_2) != HAL_OK)
  {
    Error_Handler();
  }
  PeriphClkInit.PeriphClockSelection = RCC_PERIPHCLK_ADC;
  PeriphClkInit.AdcClockSelection = RCC_ADCPCLK2_DIV6;
  if (HAL_RCCEx_PeriphCLKConfig(&PeriphClkInit) != HAL_OK)
  {
    Error_Handler();
  }
}

static void MX_ADC2_Init(void)
{

  ADC_ChannelConfTypeDef sConfig = {0};

  /** Common config
  */
  hadc2.Instance = ADC2;
  hadc2.Init.ScanConvMode = ADC_SCAN_ENABLE;
  hadc2.Init.ContinuousConvMode = DISABLE;
  hadc2.Init.DiscontinuousConvMode = DISABLE;
  hadc2.Init.ExternalTrigConv = ADC_SOFTWARE_START;
  hadc2.Init.DataAlign = ADC_DATAALIGN_RIGHT;
  hadc2.Init.NbrOfConversion = 1;
  if (HAL_ADC_Init(&hadc2) != HAL_OK)
  {
    Error_Handler();
  }

//  /** Configure Regular Channel
//  */
//  sConfig.Channel = ADC_CHANNEL_1;
//  sConfig.Rank = ADC_REGULAR_RANK_1;
//  sConfig.SamplingTime = ADC_SAMPLETIME_28CYCLES_5;
//  if (HAL_ADC_ConfigChannel(&hadc2, &sConfig) != HAL_OK)
//  {
//    Error_Handler();
//  }
//
//  /** Configure Regular Channel
//  */
//  sConfig.Channel = ADC_CHANNEL_2;
//  sConfig.Rank = ADC_REGULAR_RANK_2;
//  if (HAL_ADC_ConfigChannel(&hadc2, &sConfig) != HAL_OK)
//  {
//    Error_Handler();
//  }
//
//  /** Configure Regular Channel
//  */
//  sConfig.Channel = ADC_CHANNEL_3;
//  sConfig.Rank = ADC_REGULAR_RANK_3;
//  if (HAL_ADC_ConfigChannel(&hadc2, &sConfig) != HAL_OK)
//  {
//    Error_Handler();
//  }

}

static void MX_I2C1_Init(void)
{

  hi2c1.Instance = I2C1;
  hi2c1.Init.ClockSpeed = 100000;
  hi2c1.Init.DutyCycle = I2C_DUTYCYCLE_2;
  hi2c1.Init.OwnAddress1 = 0;
  hi2c1.Init.AddressingMode = I2C_ADDRESSINGMODE_7BIT;
  hi2c1.Init.DualAddressMode = I2C_DUALADDRESS_DISABLE;
  hi2c1.Init.OwnAddress2 = 0;
  hi2c1.Init.GeneralCallMode = I2C_GENERALCALL_DISABLE;
  hi2c1.Init.NoStretchMode = I2C_NOSTRETCH_DISABLE;
  if (HAL_I2C_Init(&hi2c1) != HAL_OK)
  {
    Error_Handler();
  }

}

static void MX_SPI1_Init(void)
{

  /* SPI1 parameter configuration*/
  hspi1.Instance = SPI1;
  hspi1.Init.Mode = SPI_MODE_MASTER;
  hspi1.Init.Direction = SPI_DIRECTION_2LINES;
  hspi1.Init.DataSize = SPI_DATASIZE_8BIT;
  hspi1.Init.CLKPolarity = SPI_POLARITY_LOW;
  hspi1.Init.CLKPhase = SPI_PHASE_1EDGE;
  hspi1.Init.NSS = SPI_NSS_SOFT;
  hspi1.Init.BaudRatePrescaler = SPI_BAUDRATEPRESCALER_256;
  hspi1.Init.FirstBit = SPI_FIRSTBIT_MSB;
  hspi1.Init.TIMode = SPI_TIMODE_DISABLE;
  hspi1.Init.CRCCalculation = SPI_CRCCALCULATION_DISABLE;
  hspi1.Init.CRCPolynomial = 10;
  if (HAL_SPI_Init(&hspi1) != HAL_OK)
  {
    Error_Handler();
  }

}

static void MX_TIM1_Init(void)
{

  TIM_ClockConfigTypeDef sClockSourceConfig = {0};
  TIM_MasterConfigTypeDef sMasterConfig = {0};

  htim1.Instance = TIM1;
  htim1.Init.Prescaler = 72-1;
  htim1.Init.CounterMode = TIM_COUNTERMODE_UP;
  htim1.Init.Period = 0xffff-1;
  htim1.Init.ClockDivision = TIM_CLOCKDIVISION_DIV1;
  htim1.Init.RepetitionCounter = 0;
  htim1.Init.AutoReloadPreload = TIM_AUTORELOAD_PRELOAD_ENABLE;
  if (HAL_TIM_Base_Init(&htim1) != HAL_OK)
  {
    Error_Handler();
  }
  sClockSourceConfig.ClockSource = TIM_CLOCKSOURCE_INTERNAL;
  if (HAL_TIM_ConfigClockSource(&htim1, &sClockSourceConfig) != HAL_OK)
  {
    Error_Handler();
  }
  sMasterConfig.MasterOutputTrigger = TIM_TRGO_RESET;
  sMasterConfig.MasterSlaveMode = TIM_MASTERSLAVEMODE_DISABLE;
  if (HAL_TIMEx_MasterConfigSynchronization(&htim1, &sMasterConfig) != HAL_OK)
  {
    Error_Handler();
  }

}

static void MX_TIM2_Init(void)
{

  TIM_ClockConfigTypeDef sClockSourceConfig = {0};
  TIM_MasterConfigTypeDef sMasterConfig = {0};

  htim2.Instance = TIM2;
  htim2.Init.Prescaler = 72-1;
  htim2.Init.CounterMode = TIM_COUNTERMODE_UP;
  htim2.Init.Period = 65535-1;
  htim2.Init.ClockDivision = TIM_CLOCKDIVISION_DIV1;
  htim2.Init.AutoReloadPreload = TIM_AUTORELOAD_PRELOAD_ENABLE;
  if (HAL_TIM_Base_Init(&htim2) != HAL_OK)
  {
    Error_Handler();
  }
  sClockSourceConfig.ClockSource = TIM_CLOCKSOURCE_INTERNAL;
  if (HAL_TIM_ConfigClockSource(&htim2, &sClockSourceConfig) != HAL_OK)
  {
    Error_Handler();
  }
  sMasterConfig.MasterOutputTrigger = TIM_TRGO_RESET;
  sMasterConfig.MasterSlaveMode = TIM_MASTERSLAVEMODE_DISABLE;
  if (HAL_TIMEx_MasterConfigSynchronization(&htim2, &sMasterConfig) != HAL_OK)
  {
    Error_Handler();
  }

}

static void MX_TIM3_Init(void)
{

  TIM_ClockConfigTypeDef sClockSourceConfig = {0};
  TIM_MasterConfigTypeDef sMasterConfig = {0};

  htim3.Instance = TIM3;
  htim3.Init.Prescaler = 7199;
  htim3.Init.CounterMode = TIM_COUNTERMODE_UP;
  htim3.Init.Period = 10;
  htim3.Init.ClockDivision = TIM_CLOCKDIVISION_DIV1;
  htim3.Init.AutoReloadPreload = TIM_AUTORELOAD_PRELOAD_ENABLE;
  if (HAL_TIM_Base_Init(&htim3) != HAL_OK)
  {
    Error_Handler();
  }
  sClockSourceConfig.ClockSource = TIM_CLOCKSOURCE_INTERNAL;
  if (HAL_TIM_ConfigClockSource(&htim3, &sClockSourceConfig) != HAL_OK)
  {
    Error_Handler();
  }
  sMasterConfig.MasterOutputTrigger = TIM_TRGO_RESET;
  sMasterConfig.MasterSlaveMode = TIM_MASTERSLAVEMODE_DISABLE;
  if (HAL_TIMEx_MasterConfigSynchronization(&htim3, &sMasterConfig) != HAL_OK)
  {
    Error_Handler();
  }

}

static void MX_TIM4_Init(void)
{

  TIM_ClockConfigTypeDef sClockSourceConfig = {0};
  TIM_MasterConfigTypeDef sMasterConfig = {0};

  htim4.Instance = TIM4;
  htim4.Init.Prescaler = 47999;
  htim4.Init.CounterMode = TIM_COUNTERMODE_UP;
  htim4.Init.Period = 255;
  htim4.Init.ClockDivision = TIM_CLOCKDIVISION_DIV1;
  htim4.Init.AutoReloadPreload = TIM_AUTORELOAD_PRELOAD_ENABLE;
  if (HAL_TIM_Base_Init(&htim4) != HAL_OK)
  {
    Error_Handler();
  }
  sClockSourceConfig.ClockSource = TIM_CLOCKSOURCE_INTERNAL;
  if (HAL_TIM_ConfigClockSource(&htim4, &sClockSourceConfig) != HAL_OK)
  {
    Error_Handler();
  }
  sMasterConfig.MasterOutputTrigger = TIM_TRGO_RESET;
  sMasterConfig.MasterSlaveMode = TIM_MASTERSLAVEMODE_DISABLE;
  if (HAL_TIMEx_MasterConfigSynchronization(&htim4, &sMasterConfig) != HAL_OK)
  {
    Error_Handler();
  }
  /* USER CODE BEGIN TIM4_Init 2 */
		HAL_TIM_PWM_Start(&htim4, TIM_CHANNEL_1);
		HAL_Delay(100); // Introduce a delay (adjust as needed)
		HAL_TIM_PWM_Start(&htim4, TIM_CHANNEL_2);
  /* USER CODE END TIM4_Init 2 */

}

static void MX_GPIO_Init(void)
{
  GPIO_InitTypeDef GPIO_InitStruct = {0};

  /* GPIO Ports Clock Enable */
  __HAL_RCC_GPIOD_CLK_ENABLE();
  __HAL_RCC_GPIOC_CLK_ENABLE();
  __HAL_RCC_GPIOA_CLK_ENABLE();
  __HAL_RCC_GPIOB_CLK_ENABLE();

  /*Configure GPIO pin Output Level */
  HAL_GPIO_WritePin(GPIOB, GPIO_PIN_11|GPIO_PIN_3|GPIO_PIN_6|GPIO_PIN_7, GPIO_PIN_RESET);

  /*Configure GPIO pins : PC1 PC2 PC3 SET_1_Pin */
  GPIO_InitStruct.Pin = GPIO_PIN_1|GPIO_PIN_2|GPIO_PIN_3|SET_1_Pin;
  GPIO_InitStruct.Mode = GPIO_MODE_INPUT;
  GPIO_InitStruct.Pull = GPIO_PULLDOWN;
  HAL_GPIO_Init(GPIOC, &GPIO_InitStruct);

  /*Configure GPIO pins : SET_1000_Pin SET_100_Pin SET_10_Pin */
  GPIO_InitStruct.Pin = SET_1000_Pin|SET_100_Pin|SET_10_Pin;
  GPIO_InitStruct.Mode = GPIO_MODE_INPUT;
  GPIO_InitStruct.Pull = GPIO_PULLDOWN;
  HAL_GPIO_Init(GPIOB, &GPIO_InitStruct);

  /*Configure GPIO pin : PB11 */
  GPIO_InitStruct.Pin = GPIO_PIN_11;
  GPIO_InitStruct.Mode = GPIO_MODE_OUTPUT_PP;
  GPIO_InitStruct.Pull = GPIO_PULLDOWN;
  GPIO_InitStruct.Speed = GPIO_SPEED_FREQ_LOW;
  HAL_GPIO_Init(GPIOB, &GPIO_InitStruct);

  /*Configure GPIO pin : PB3 */
  GPIO_InitStruct.Pin = GPIO_PIN_3;
  GPIO_InitStruct.Mode = GPIO_MODE_OUTPUT_PP;
  GPIO_InitStruct.Pull = GPIO_NOPULL;
  GPIO_InitStruct.Speed = GPIO_SPEED_FREQ_HIGH;
  HAL_GPIO_Init(GPIOB, &GPIO_InitStruct);

  /*Configure GPIO pins : PB6 PB7 */
  GPIO_InitStruct.Pin = GPIO_PIN_6|GPIO_PIN_7;
  GPIO_InitStruct.Mode = GPIO_MODE_OUTPUT_PP;
  GPIO_InitStruct.Pull = GPIO_NOPULL;
  GPIO_InitStruct.Speed = GPIO_SPEED_FREQ_LOW;
  HAL_GPIO_Init(GPIOB, &GPIO_InitStruct);

/* USER CODE BEGIN MX_GPIO_Init_2 */
		GPIO_InitStruct.Pin = GPIO_PIN_3;
		GPIO_InitStruct.Mode = GPIO_MODE_AF_PP; // Alternate function push-pull
		GPIO_InitStruct.Speed = GPIO_SPEED_FREQ_HIGH;
		HAL_GPIO_Init(GPIOB, &GPIO_InitStruct);

/* USER CODE END MX_GPIO_Init_2 */
}

void Error_Handler(void)
{
		__disable_irq();
		while (1)
		{
		}
}
